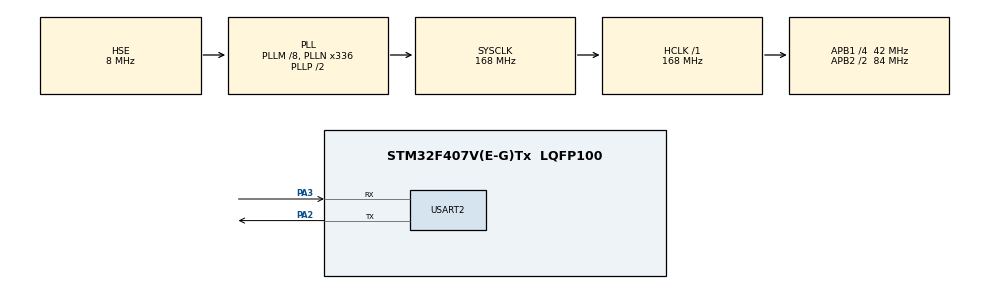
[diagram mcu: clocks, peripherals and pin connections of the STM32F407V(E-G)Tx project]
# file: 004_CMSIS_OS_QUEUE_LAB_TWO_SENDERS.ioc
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FREERTOS.Queues01=Queue1,256,uint8_t,0,Dynamic,NULL,NULL;Queue02,16,Data,0,Dynamic,NULL,NULL
FREERTOS.Tasks01=Sender1,0,128,StartSender1,Default,NULL,Dynamic,NULL,NULL;Receiver,1,128,StartReceiver,Default,NULL,Dynamic,NULL,NULL;Sender2,0,128,StartSender2,Default,NULL,Dynamic,NULL,NULL
FREERTOS.configUSE_NEWLIB_REENTRANT=1
Mcu.Family=STM32F4
Mcu.Name=STM32F407V(E-G)Tx
Mcu.Package=LQFP100
NVIC.PriorityGroup=NVIC_PRIORITYGROUP_4
NVIC.TIM8_TRG_COM_TIM14_IRQn=true\:15\:0\:false\:false\:true\:false\:false\:true\:true
NVIC.TimeBase=TIM8_TRG_COM_TIM14_IRQn
NVIC.TimeBaseIP=TIM14
NVIC.USART2_IRQn=true\:5\:0\:false\:false\:true\:true\:true\:true\:true
PA2.Mode=Asynchronous
PA2.Signal=USART2_TX
PA3.Mode=Asynchronous
PA3.Signal=USART2_RX
PH0-OSC_IN.Mode=HSE-External-Oscillator
PH0-OSC_IN.Signal=RCC_OSC_IN
PH1-OSC_OUT.Mode=HSE-External-Oscillator
PH1-OSC_OUT.Signal=RCC_OSC_OUT
ProjectManager.HeapSize=0x200
ProjectManager.StackSize=0x400
ProjectManager.TargetToolchain=STM32CubeIDE
RCC.48MHZClocksFreq_Value=48000000
RCC.AHBFreq_Value=168000000
RCC.APB1CLKDivider=RCC_HCLK_DIV4
RCC.APB1Freq_Value=42000000
RCC.APB1TimFreq_Value=84000000
RCC.APB2CLKDivider=RCC_HCLK_DIV2
RCC.APB2Freq_Value=84000000
RCC.APB2TimFreq_Value=168000000
RCC.CortexFreq_Value=168000000
RCC.HCLKFreq_Value=168000000
RCC.HSE_VALUE=8000000
RCC.HSI_VALUE=16000000
RCC.LSE_VALUE=32768
RCC.PLLM=8
RCC.PLLN=336
RCC.PLLQ=7
RCC.PLLSourceVirtual=RCC_PLLSOURCE_HSE
RCC.SYSCLKFreq_VALUE=168000000
RCC.SYSCLKSource=RCC_SYSCLKSOURCE_PLLCLK
RCC.VCOOutputFreq_Value=336000000
USART2.VirtualMode=VM_ASYNC
VP_FREERTOS_VS_CMSIS_V1.Mode=CMSIS_V1
VP_SYS_VS_tim14.Mode=TIM14
board=STM32F407G-DISC1

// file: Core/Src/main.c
/* USER CODE BEGIN Header */
/**
  ******************************************************************************
  * @file           : main.c
  * @brief          : Main program body
  ******************************************************************************
  * @attention
  *
  * Copyright (c) 2023 STMicroelectronics.
  * All rights reserved.
  *
  * This software is licensed under terms that can be found in the LICENSE file
  * in the root directory of this software component.
  * If no LICENSE file comes with this software, it is provided AS-IS.
  *
  ******************************************************************************
  */
/* USER CODE END Header */
#include "main.h"
#include "cmsis_os.h"

/* USER CODE BEGIN Includes */
#include <string.h>
#include <stdio.h>
/* USER CODE END Includes */

/* USER CODE BEGIN PD */
typedef struct
{
	uint16_t Value;
	uint8_t Source;
}Data;
/* USER CODE END PD */

UART_HandleTypeDef huart2;

osThreadId Sender1Handle;
osThreadId ReceiverHandle;
osThreadId Sender2Handle;
osMessageQId Queue1Handle;
osMessageQId Queue02Handle;
/* USER CODE BEGIN PV */
Data DataToSend1 = {2023, 1};
Data DataToSend2 = {2024, 2};
/* USER CODE END PV */

void SystemClock_Config(void);
static void MX_GPIO_Init(void);
static void MX_USART2_UART_Init(void);
void StartSender1(void const * argument);
void StartReceiver(void const * argument);
void StartSender2(void const * argument);

int main(void)
{

  /* MCU Configuration--------------------------------------------------------*/

  /* Reset of all peripherals, Initializes the Flash interface and the Systick. */
  HAL_Init();

  /* Configure the system clock */
  SystemClock_Config();

  /* Initialize all configured peripherals */
  MX_GPIO_Init();
  MX_USART2_UART_Init();

  /* Create the queue(s) */
  /* definition and creation of Queue1 */
  osMessageQDef(Queue1, 256, uint8_t);
  Queue1Handle = osMessageCreate(osMessageQ(Queue1), NULL);

  /* definition and creation of Queue02 */
  osMessageQDef(Queue02, 16, Data);
  Queue02Handle = osMessageCreate(osMessageQ(Queue02), NULL);

  /* Create the thread(s) */
  /* definition and creation of Sender1 */
  osThreadDef(Sender1, StartSender1, osPriorityNormal, 0, 128);
  Sender1Handle = osThreadCreate(osThread(Sender1), NULL);

  /* definition and creation of Receiver */
  osThreadDef(Receiver, StartReceiver, osPriorityAboveNormal, 0, 128);
  ReceiverHandle = osThreadCreate(osThread(Receiver), NULL);

  /* definition and creation of Sender2 */
  osThreadDef(Sender2, StartSender2, osPriorityNormal, 0, 128);
  Sender2Handle = osThreadCreate(osThread(Sender2), NULL);

  /* Start scheduler */
  osKernelStart();
  /* We should never get here as control is now taken by the scheduler */
  /* Infinite loop */
  while (1)
  {

  }
}

void SystemClock_Config(void)
{
  RCC_OscInitTypeDef RCC_OscInitStruct = {0};
  RCC_ClkInitTypeDef RCC_ClkInitStruct = {0};

  /** Configure the main internal regulator output voltage
  */
  __HAL_RCC_PWR_CLK_ENABLE();
  __HAL_PWR_VOLTAGESCALING_CONFIG(PWR_REGULATOR_VOLTAGE_SCALE1);

  /** Initializes the RCC Oscillators according to the specified parameters
  * in the RCC_OscInitTypeDef structure.
  */
  RCC_OscInitStruct.OscillatorType = RCC_OSCILLATORTYPE_HSE;
  RCC_OscInitStruct.HSEState = RCC_HSE_ON;
  RCC_OscInitStruct.PLL.PLLState = RCC_PLL_ON;
  RCC_OscInitStruct.PLL.PLLSource = RCC_PLLSOURCE_HSE;
  RCC_OscInitStruct.PLL.PLLM = 8;
  RCC_OscInitStruct.PLL.PLLN = 336;
  RCC_OscInitStruct.PLL.PLLP = RCC_PLLP_DIV2;
  RCC_OscInitStruct.PLL.PLLQ = 7;
  if (HAL_RCC_OscConfig(&RCC_OscInitStruct) != HAL_OK)
  {
    Error_Handler();
  }

  /** Initializes the CPU, AHB and APB buses clocks
  */
  RCC_ClkInitStruct.ClockType = RCC_CLOCKTYPE_HCLK|RCC_CLOCKTYPE_SYSCLK
                              |RCC_CLOCKTYPE_PCLK1|RCC_CLOCKTYPE_PCLK2;
  RCC_ClkInitStruct.SYSCLKSource = RCC_SYSCLKSOURCE_PLLCLK;
  RCC_ClkInitStruct.AHBCLKDivider = RCC_SYSCLK_DIV1;
  RCC_ClkInitStruct.APB1CLKDivider = RCC_HCLK_DIV4;
  RCC_ClkInitStruct.APB2CLKDivider = RCC_HCLK_DIV2;

  if (HAL_RCC_ClockConfig(&RCC_ClkInitStruct, FLASH_LATENCY_5) != HAL_OK)
  {
    Error_Handler();
  }
}

static void MX_USART2_UART_Init(void)
{

  huart2.Instance = USART2;
  huart2.Init.BaudRate = 115200;
  huart2.Init.WordLength = UART_WORDLENGTH_8B;
  huart2.Init.StopBits = UART_STOPBITS_1;
  huart2.Init.Parity = UART_PARITY_NONE;
  huart2.Init.Mode = UART_MODE_TX_RX;
  huart2.Init.HwFlowCtl = UART_HWCONTROL_NONE;
  huart2.Init.OverSampling = UART_OVERSAMPLING_16;
  if (HAL_UART_Init(&huart2) != HAL_OK)
  {
    Error_Handler();
  }

}

static void MX_GPIO_Init(void)
{

  /* GPIO Ports Clock Enable */
  __HAL_RCC_GPIOH_CLK_ENABLE();
  __HAL_RCC_GPIOA_CLK_ENABLE();

}

void StartSender1(void const * argument)
{
  /* USER CODE BEGIN 5 */
  /* Infinite loop */
  for(;;)
  {
	  osMessagePut(Queue1Handle, 0x1,200);
	  osMessagePut(Queue02Handle, (uint32_t)&DataToSend1, 200);
	  osDelay(1000);
  }
  /* USER CODE END 5 */
}

void StartReceiver(void const * argument)
{
  /* USER CODE BEGIN StartReceiver */
  /* Infinite loop */
	osEvent retvalue;
	char buffer[100];
	for(;;)
	{
		retvalue = osMessageGet(Queue1Handle,4000);
		HAL_UART_Transmit(&huart2, (uint8_t*)&(retvalue.value.v), 1,HAL_MAX_DELAY);
		osDelay(1);
		retvalue = osMessageGet(Queue02Handle, 1000);
		if(((Data*)retvalue.value.p)->Source == 1)
		{
			sprintf(buffer, "Received message from Sender 1 -> %d",((Data*)(retvalue.value.p))->Value);
			HAL_UART_Transmit(&huart2,(uint8_t*)buffer, strlen(buffer), HAL_MAX_DELAY);
		}
		else
		{
			sprintf(buffer, "Received message from Sender 2 -> %u",((Data*)(retvalue.value.p))->Value);
			HAL_UART_Transmit(&huart2,(uint8_t*)buffer, strlen(buffer), HAL_MAX_DELAY);
		}
		osDelay(100);
	}
  /* USER CODE END StartReceiver */
}

void StartSender2(void const * argument)
{
  /* USER CODE BEGIN StartSender2 */
  /* Infinite loop */
  for(;;)
  {
	  osMessagePut(Queue1Handle, 0x2,200);
	  osMessagePut(Queue02Handle, (uint32_t)&DataToSend2,200);
	  osDelay(1000);
  }
  /* USER CODE END StartSender2 */
}

/**.
  * @brief  Period elapsed callback in non blocking mode
  * @note   This function is called  when TIM14 interrupt took place, inside
  * HAL_TIM_IRQHandler(). It makes a direct call to HAL_IncTick() to increment
  * a global variable "uwTick" used as application time base.
  * @param  htim : TIM handle
  * @retval None
  */
void HAL_TIM_PeriodElapsedCallback(TIM_HandleTypeDef *htim)
{
  if (htim->Instance == TIM14) {
    HAL_IncTick();
  }
}

void Error_Handler(void)
{
  __disable_irq();
  while (1)
  {
  }
}
